# EFM32PG22C200F128IM40 register map
Vendor: Silicon Labs; Series: EFM32; File version: C
Registers are 32-bit, read-write, reset 0x0 unless marked. A register's access mark holds for its fields unless they carry their own. Offsets are from the block's base; [hi:lo] are bit positions; 'fields as' and 'values as' point back to an identical list.

## DCDC_S — DCDC_S Registers
Base 0x40094000
Same registers: DCDC_NS 0x50094000
0x00 IPVERSION ro
0x04 EN — Enable
  [0] EN
    0=DISABLE; 1=ENABLE
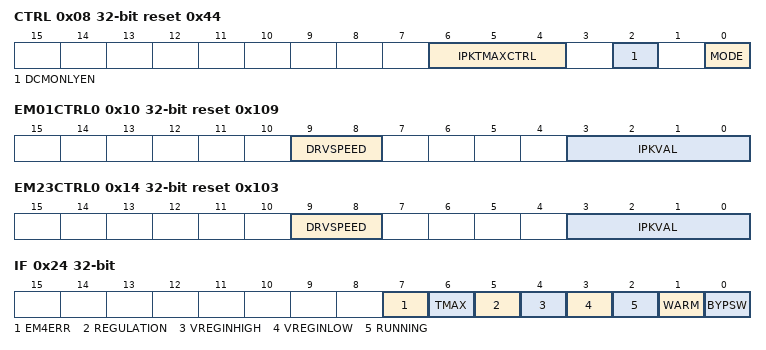
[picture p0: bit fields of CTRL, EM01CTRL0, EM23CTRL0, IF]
0x08 CTRL reset 0x44 — Control
  [6:4] IPKTMAXCTRL — Peak Current Timeout Control
    0=OFF (Ton_max disabled); 1=TMAX_0P35us (0.35us); 2=TMAX_0P63us (0.63us); 3=TMAX_0P91us (0.91us); 4=TMAX_1P19us (1.19us); 5=TMAX_1P47us (1.47us); 6=TMAX_1P75us (1.75us); 7=TMAX_2P03us (2.03us)
  [2] DCMONLYEN — DCDC DCM Only Enable
    0=DUALMODE (Support higher load current at lower battery voltage by working in CCM mode); 1=DCMONLYEN (DCM only mode for normal operation, this is the default setting)
  [0] MODE — DCDC/Bypass Mode Control
    0=BYPASS (DCDC is OFF, bypass switch is enabled); 1=DCDCREGULATION (Request DCDC regulation, bypass switch disabled)
0x10 EM01CTRL0 reset 0x109 — EM01 Configurations
  [9:8] DRVSPEED — EM01 Drive Speed Setting
    0=BEST_EMI (Lowest Efficiency, Lowest EMI.. Small decrease in efficiency from default setting); 1=DEFAULT_SETTING (Default Efficiency, Acceptable EMI level); 2=INTERMEDIATE (Small increase in efficiency from the default setting); 3=BEST_EFFICIENCY (Highest Efficiency, Highest EMI.. Small increase in efficiency from INTERMEDIATE setting)
  [3:0] IPKVAL — EM01 Peak Current Setting
    3=Load36mA (Ipeak = 90mA, Iload = 36mA); 4=Load40mA (Ipeak = 100mA, Iload = 40mA); 5=Load44mA (Ipeak = 110mA, Iload = 44mA); 6=Load48mA (Ipeak = 120mA, Iload = 48mA); 7=Load52mA (Ipeak = 130mA, Iload = 52mA); 8=Load56mA (Ipeak = 140mA, Iload = 56mA); 9=Load60mA (Ipeak = 150mA, Iload = 60mA)
0x14 EM23CTRL0 reset 0x103 — EM23 Configurations
  [9:8] DRVSPEED — EM23 Drive Speed Setting
    values as EM01CTRL0.DRVSPEED
  [3:0] IPKVAL — EM23 Peak Current Setting
    3=LOAD5MA (Ipeak = 90mA, Iload = 5 mA); 9=LOAD10MA (Ipeak = 150mA, Iload = 10 mA)
0x24 IF — Interrupt Flags
  [7] EM4ERR — EM4 Entry Request Error
  [6] TMAX — Ton_max Timeout Reached
  [5] REGULATION — DCDC in regulation
  [4] VREGINHIGH — VREGVDD above threshold
  [3] VREGINLOW — VREGVDD below threshold
  [2] RUNNING — DCDC Running
  [1] WARM — DCDC Warmup Time Done
  [0] BYPSW — Bypass Switch Enabled
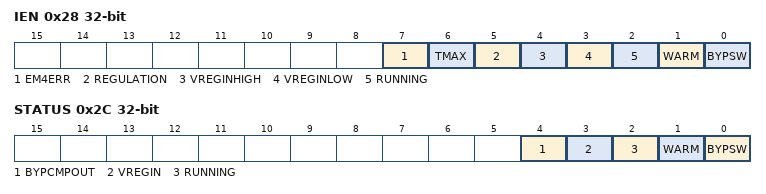
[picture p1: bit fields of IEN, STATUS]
0x28 IEN — Interrupt Enable
  [7] EM4ERR — EM4 Entry Req Interrupt Enable
  [6] TMAX — Ton_max Timeout Interrupt Enable
  [5] REGULATION — DCDC in Regulation Interrupt Enable
  [4] VREGINHIGH — VREGVDD above threshold Interrupt Enable
  [3] VREGINLOW — VREGVDD below threshold Interrupt Enable
  [2] RUNNING — DCDC Running Interrupt Enable
  [1] WARM — DCDC Warmup Time Done Interrupt Enable
  [0] BYPSW — Bypass Switch Enabled Interrupt Enable
0x2C STATUS ro — DCDC Status Register
  [4] BYPCMPOUT — Bypass Comparator Output
  [3] VREGIN — VREGVDD comparator status
  [2] RUNNING — DCDC is running
  [1] WARM — DCDC Warmup Done
  [0] BYPSW — Bypass Switch is currently enabled
0x40 LOCK wo
  [15:0] LOCKKEY — Configuration Lock Key
    0xABCD=UNLOCKKEY (Value to write to unlock)
0x44 LOCKSTATUS ro
  [0] LOCK — Lock Status
    0=UNLOCKED (Unlocked State); 1=LOCKED (LOCKED STATE)

## PDM_S — PDM_S Registers
Base 0x40098000
Same registers: PDM_NS 0x50098000
0x00 IPVERSION ro
0x04 EN
  [0] EN — PDM enable
    0=DISABLE (Disable module); 1=ENABLE (Enable module)
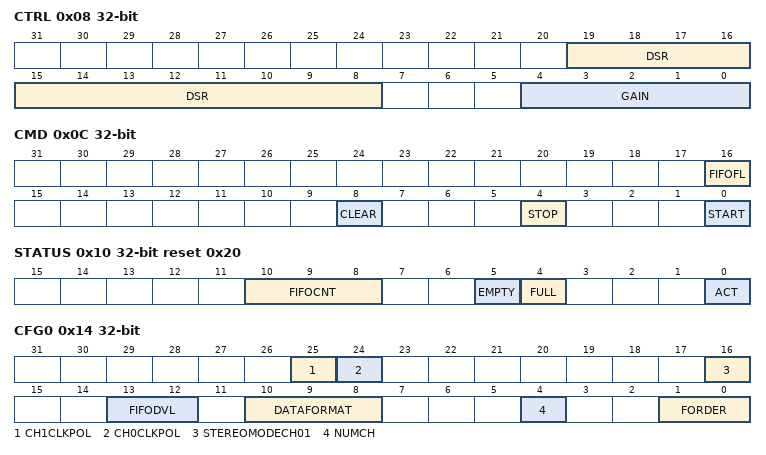
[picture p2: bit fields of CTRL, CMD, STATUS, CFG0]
0x08 CTRL
  [19:8] DSR — Down sampling rate of Decimation filter
  [4:0] GAIN — Selects Gain factor of DCF
0x0C CMD wo
  [16] FIFOFL — FIFO Flush
  [8] CLEAR — Clear DCF
  [4] STOP — Stop DCF
  [0] START — Start DCF
0x10 STATUS ro reset 0x20
  [10:8] FIFOCNT
  [5] EMPTY — FIFO EMPTY Status
  [4] FULL — FIFO FULL Status
  [0] ACT — PDM is active
0x14 CFG0
  [25] CH1CLKPOL — CH1 CLK Polarity
    0=NORMAL (Input data clocked on rising clock edge.); 1=INVERT (Input data clocked on falling clock edge.)
  [24] CH0CLKPOL — CH0 CLK Polarity
    values as CH1CLKPOL
  [16] STEREOMODECH01
    0=DISABLE (No Stereo mode.); 1=CH01ENABLE (CH0 and CH1 in Stereo mode.)
  [13:12] FIFODVL — Data Valid level in FIFO
    0=ONE (Atleast one word.); 1=TWO (Two words.); 2=THREE (Three words.); 3=FOUR (Four words.)
  [10:8] DATAFORMAT — Filter output format
    0=RIGHT16 (Right aligned 16-bit, left bits are sign extended.); 1=DOUBLE16 (Pack two 16-bit samples into one 32-bit word.); 2=RIGHT24 (Right aligned 24bit, left bits are sign extended.); 3=FULL32BIT (32 bit data.); 4=LEFT16 (Left aligned 16-bit, right bits are zeros.); 5=LEFT24 (Left aligned 24-bit, right bits are zeros.); 6=RAW32BIT (RAW 32 bit data from Integrator.)
  [4] NUMCH — Number of Channels
    0=ONE (One channel.); 1=TWO (Two channels.)
  [1:0] FORDER — Filter order
    0=SECOND (Second order filter.); 1=THIRD (Third order filter.); 2=FOURTH (Fourth order filter.); 3=FIFTH (Fifth order filter.)
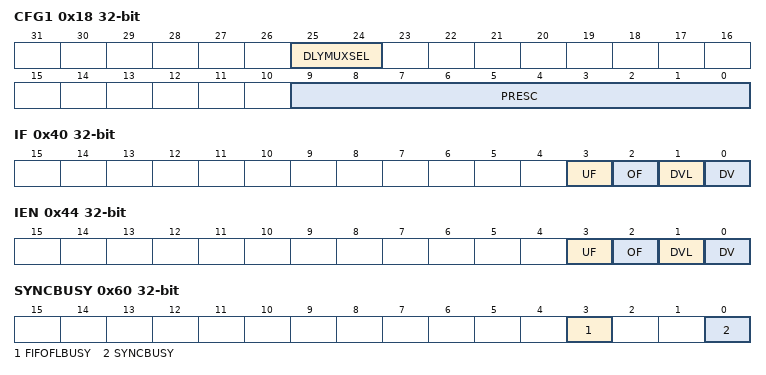
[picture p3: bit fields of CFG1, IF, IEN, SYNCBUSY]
0x18 CFG1
  [25:24] DLYMUXSEL — Data delay buffer mux selection
  [9:0] PRESC — Prescalar Setting for PDM sample
0x20 RXDATA ro
  [31:0] RXDATA — PDM received data
0x40 IF
  [3] UF — FIFO Undeflow Interrupt Flag
  [2] OF — FIFO Overflow Interrupt Flag
  [1] DVL — Data Valid Level Interrupt Flag
  [0] DV — Data Valid Interrupt Flag
0x44 IEN
  [3] UF — FIFO Undeflow Interrupt Enable
  [2] OF — FIFO Overflow Interrupt Enable
  [1] DVL — Data Valid Level Interrupt Enable
  [0] DV — Data Valid Interrupt Enable
0x60 SYNCBUSY ro
  [3] FIFOFLBUSY — FIFO Flush Sync busy
  [0] SYNCBUSY
